# STM32N655xx register map
File version: 1.0
Registers are 32-bit, read-write, reset 0x0 unless marked. A register's access mark holds for its fields unless they carry their own. Offsets are from the block's base; [hi:lo] are bit positions; {n}, {i} and the like mark numbered series; 'fields as' and 'values as' point back to an identical list.

## DMA2D — DMA2D Controller
Base 0x48021000
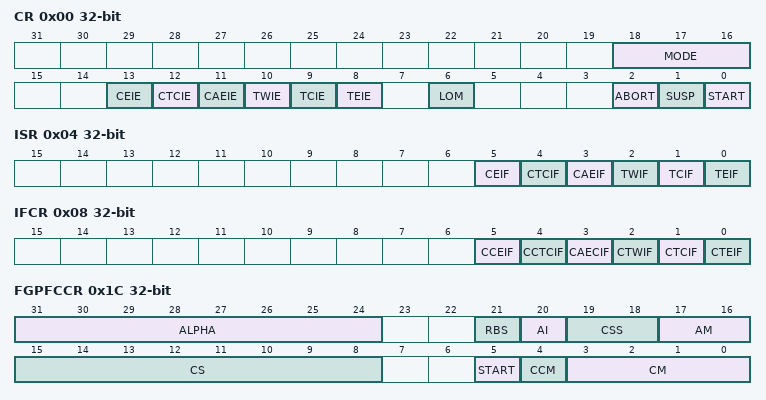
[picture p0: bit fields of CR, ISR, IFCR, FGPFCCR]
0x00 CR — DMA2D Control Register
  [18:16] MODE — DMA2D Mode[2:0]
    0=M2M (DMA2D memory to memory transfer mode); 1=M2M_PFC (DMA2D memory to memory with pixel format conversion transfer mode); 2=M2M_BLEND (DMA2D memory to memory with blending transfer mode); 3=R2M (DMA2D register to memory transfer mode); 4=M2M_BLEND_FIXED_COLOR_FG (DMA2D memory to memory with blending transfer mode and fixed color foreground); 5=M2M_BLEND_FIXED_COLOR_BG (DMA2D memory to memory with blending transfer mode and fixed color background)
  [13] CEIE — Configuration Error Interrupt Enable
  [12] CTCIE — CLUT Transfer Complete Interrupt Enable
  [11] CAEIE — CLUT Access Error Interrupt Enable
  [10] TWIE — Transfer Watermark Interrupt Enable
  [9] TCIE — Transfer Complete Interrupt Enable
  [8] TEIE — Transfer Error Interrupt Enable
  [6] LOM — Line Offset Mode
    0=PIXELS (Line offsets are expressed in pixels); 1=BYTES (Line offsets are expressed in bytes)
  [2] ABORT — Abort transfer
  [1] SUSP — Suspend transfer
  [0] START — Start transfer
0x04 ISR — DMA2D Interrupt Status Register
  [5] CEIF — Configuration Error Interrupt Flag
  [4] CTCIF — CLUT Transfer Complete Interrupt Flag
  [3] CAEIF — CLUT Access Error Interrupt Flag
  [2] TWIF — Transfer Watermark Interrupt Flag
  [1] TCIF — Transfer Complete Interrupt Flag
  [0] TEIF — Transfer Error Interrupt Flag
0x08 IFCR — DMA2D Interrupt Flag Clear Register
  [5] CCEIF — Clears Configuration Error Interrupt Flag
  [4] CCTCIF — Clears CLUT Transfer Complete Interrupt Flag
  [3] CAECIF — Clears CLUT Access Error Interrupt Flag
  [2] CTWIF — Clears Transfer Watermark Interrupt Flag
  [1] CTCIF — Clears Transfer Complete Interrupt Flag
  [0] CTEIF — Clears Transfer Error Interrupt Flag
0x0C FGMAR — DMA2D Foreground Memory Address Register
  [31:0] MA — Memory Address
0x10 FGOR — DMA2D Foreground
  [15:0] LO — Line Offset
0x14 BGMAR — DMA2D Background Memory Address Register
  [31:0] MA — Memory Address
0x18 BGOR — DMA2D Background
  [15:0] LO — Line Offset
0x1C FGPFCCR — DMA2D Foreground PFC Control Register
  [31:24] ALPHA — Alpha value
  [21] RBS — Red Blue Swap
    0=REGULAR (RGB or ARGB); 1=SWAP (BGR or ABGR)
  [20] AI — Alpha Inverted
    0=REGULAR (Regular alpha); 1=INVERTED (Inverted alpha)
  [19:18] CSS — Chroma Sub-Sampling
    0=No chroma sub-sampling 4:4:4; 1=chroma sub-sampling 4:2:2; 2=chroma sub-sampling 4:2:0
  [17:16] AM — Alpha mode AM[1:0]
    0=NO_MODIF (No modification of the alpha channel value); 1=REPLACE; 2=COMBINE
  [15:8] CS — CLUT size
  [5] START
  [4] CCM — CLUT Color mode
    0=ARGB8888; 1=RGB888
  [3:0] CM — Input color mode CM[3:0]
    0=ARGB8888; 1=RGB888; 2=RGB565; 3=ARGB1555; 4=ARGB4444; 5=L8; 6=AL44; 7=AL88; 8=L4; 9=A8; 10=A4
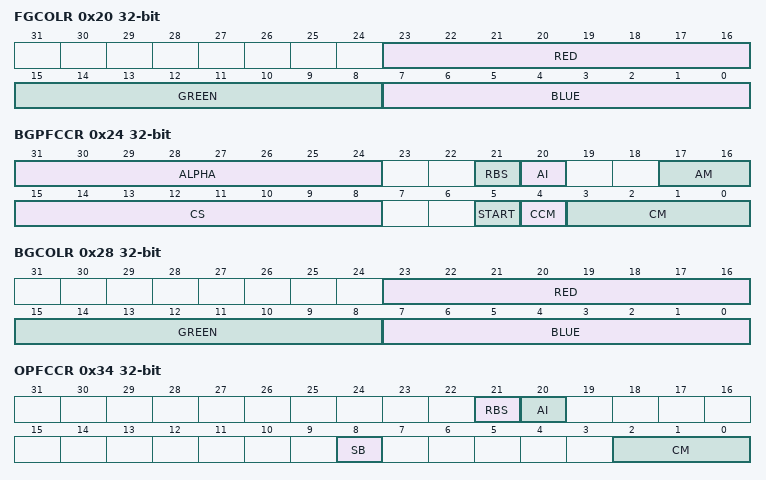
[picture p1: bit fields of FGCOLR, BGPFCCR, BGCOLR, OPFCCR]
0x20 FGCOLR — DMA2D Foreground Color Register
  [23:16] RED — Red Value
  [15:8] GREEN — Green Value
  [7:0] BLUE — Blue Value
0x24 BGPFCCR — DMA2D Background PFC Control Register
  [31:24] ALPHA — Alpha value
  [21] RBS — Red Blue Swap
    0=REGULAR (RGB or ARGB); 1=SWAP (BGR or ABGR)
  [20] AI — Alpha Inverted
    0=REGULAR (Regular alpha); 1=INVERTED (Inverted alpha)
  [17:16] AM — Alpha mode AM[1:0]
    values as FGPFCCR.AM
  [15:8] CS — CLUT size
  [5] START
  [4] CCM — CLUT Color mode
    0=ARGB8888; 1=RGB888
  [3:0] CM — Input color mode CM[3:0]
    values as FGPFCCR.CM
0x28 BGCOLR — DMA2D Background Color Register
  fields as FGCOLR
0x2C FGCMAR — DMA2D Foreground CLUT Memory Address Register
  [31:0] MA — Memory Address
0x30 BGCMAR — DMA2D Background CLUT Memory Address Register
  [31:0] MA — Memory Address
0x34 OPFCCR — DMA2D Output PFC Control Register
  [21] RBS — Red Blue Swap
    0=REGULAR (RGB or ARGB); 1=SWAP (BGR or ABGR)
  [20] AI — Alpha Inverted
    0=REGULAR (Regular alpha); 1=INVERTED (Inverted alpha)
  [8] SB — Swap Bytes
    0=REGULAR (Regular order); 1=TWO_BY_TWO (Bytes swapped two by two)
  [2:0] CM — Color mode CM[2:0]
    0=ARGB8888; 1=RGB888; 2=RGB565; 3=ARGB1555; 4=ARGB4444
0x38 OCOLR — DMA2D Output Color Register
0x3C OMAR — DMA2D Output Memory Address Register
  [31:0] MA — Memory Address
0x40 OOR — DMA2D Output
  [15:0] LO — Line Offset
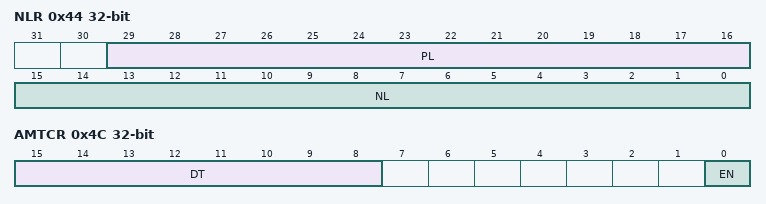
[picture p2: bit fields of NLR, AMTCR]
0x44 NLR — DMA2D Number of Line Register
  [29:16] PL — Pixel per Lines
  [15:0] NL — Number of Lines
0x48 LWR — DMA2D Line Watermark Register
  [15:0] LW — Line Watermark
0x4C AMTCR — DMA2D AHB Master Timer Configuration Register
  [15:8] DT — Dead Time
  [0] EN — Enable
{0x400+4i} FGCLUT[{i}] (i=0..255)
{0x800+4i} BGCLUT[{i}] (i=0..255)
